AUTOSAR XML (schema 4-0-3)
standard types defined: Boolean, UInt16, UInt32, UInt8
package /AUTOSAR_Platform/DataConstrs
  range DC_Boolean: raw 0..1
  range DC_UInt16: raw 0..65535
  range DC_UInt8: raw 0..255
package /PATAC/MSM/ComponentTypes
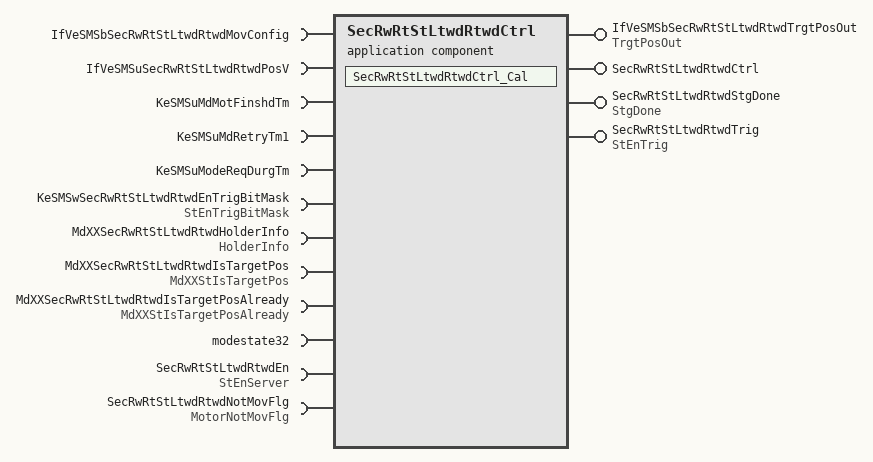
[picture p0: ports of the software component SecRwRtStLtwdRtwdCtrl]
  application sw component type SecRwRtStLtwdRtwdCtrl
    4 x provide port:
      IfVeSMSbSecRwRtStLtwdRtwdTrgtPosOut: nonqueued-sender-com-spec=data-element=TrgtPosOut/Val, provided-interface=TrgtPosOut
      SecRwRtStLtwdRtwdCtrl: server-com-spec{operation=Cal, queue-length=1}, provided-interface=SecRwRtStLtwdRtwdCtrl
      SecRwRtStLtwdRtwdStgDone: nonqueued-sender-com-spec{data-element=StgDone/Val, init-value=0}, provided-interface=StgDone
      SecRwRtStLtwdRtwdTrig: nonqueued-sender-com-spec{data-element=StEnTrig/Val, init-value=0}, provided-interface=StEnTrig
    12 x require port:
      IfVeSMSbSecRwRtStLtwdRtwdMovConfig: nonqueued-receiver-com-spec{data-element=IfVeSMSbSecRwRtStLtwdRtwdMovConfig/Val, filter=data-filter-type=ALWAYS, init-value=0}, required-interface=IfVeSMSbSecRwRtStLtwdRtwdMovConfig
      IfVeSMSuSecRwRtStLtwdRtwdPosV: nonqueued-receiver-com-spec{data-element=IfVeSMSuSecRwRtStLtwdRtwdPosV/Val, filter=data-filter-type=ALWAYS, init-value=0}, required-interface=IfVeSMSuSecRwRtStLtwdRtwdPosV
      KeSMSuMdMotFinshdTm: parameter-require-com-spec{init-value=0, parameter=KeSMSuMdMotFinshdTm/Val}, required-interface=KeSMSuMdMotFinshdTm
      KeSMSuMdRetryTm1: parameter-require-com-spec{init-value=0, parameter=KeSMSuMdRetryTm1/Val}, required-interface=KeSMSuMdRetryTm1
      KeSMSuModeReqDurgTm: parameter-require-com-spec{init-value=0, parameter=KeSMSuModeReqDurgTm/Val}, required-interface=KeSMSuModeReqDurgTm
      KeSMSwSecRwRtStLtwdRtwdEnTrigBitMask: parameter-require-com-spec{init-value=6153, parameter=StEnTrigBitMask/Val}, required-interface=StEnTrigBitMask
      MdXXSecRwRtStLtwdRtwdHolderInfo: nonqueued-receiver-com-spec{data-element=HolderInfo/Val, filter=data-filter-type=ALWAYS, init-value=0}, required-interface=HolderInfo
      MdXXSecRwRtStLtwdRtwdIsTargetPos: nonqueued-receiver-com-spec{data-element=MdXXStIsTargetPos/Val, filter=data-filter-type=ALWAYS, init-value=0}, required-interface=MdXXStIsTargetPos
      MdXXSecRwRtStLtwdRtwdIsTargetPosAlready: nonqueued-receiver-com-spec{data-element=MdXXStIsTargetPosAlready/Val, filter=data-filter-type=ALWAYS, init-value=0}, required-interface=MdXXStIsTargetPosAlready
      modestate32: nonqueued-receiver-com-spec{data-element=modestate32/Val, filter=data-filter-type=ALWAYS, init-value=0}, required-interface=modestate32
      SecRwRtStLtwdRtwdEn: required-com-specs=[Clear, Get, Set], required-interface=StEnServer
      SecRwRtStLtwdRtwdNotMovFlg: nonqueued-receiver-com-spec{data-element=MotorNotMovFlg/Val, filter=data-filter-type=ALWAYS, init-value=0}, required-interface=MotorNotMovFlg
    behavior SecRwRtStLtwdRtwdCtrl_InternalBehavior
      operation invoked event OIT_SecRwRtStLtwdRtwdCtrl_Cal_SecRwRtStLtwdRtwdCtrl_Cal: start-on-event=SecRwRtStLtwdRtwdCtrl_Cal, operation=SecRwRtStLtwdRtwdCtrl.Cal
      runnable SecRwRtStLtwdRtwdCtrl_Cal
        data-receive-point-by-arguments:
          7 x access:
            REC_IfVeSMSbSecRwRtStLtwdRtwdMovConfig_Val: accessed-variable=IfVeSMSbSecRwRtStLtwdRtwdMovConfig.Val
            REC_IfVeSMSuSecRwRtStLtwdRtwdPosV_Val: accessed-variable=IfVeSMSuSecRwRtStLtwdRtwdPosV.Val
            REC_MdXXSecRwRtStLtwdRtwdHolderInfo_Val: accessed-variable=MdXXSecRwRtStLtwdRtwdHolderInfo.Val
            REC_MdXXSecRwRtStLtwdRtwdIsTargetPos_Val: accessed-variable=MdXXSecRwRtStLtwdRtwdIsTargetPos.Val
            REC_MdXXSecRwRtStLtwdRtwdIsTargetPosAlready_Val: accessed-variable=MdXXSecRwRtStLtwdRtwdIsTargetPosAlready.Val
            REC_modestate32_Val: accessed-variable=modestate32.Val
            REC_SecRwRtStLtwdRtwdNotMovFlg_Val: accessed-variable=SecRwRtStLtwdRtwdNotMovFlg.Val
        data-send-points:
          access SEND_IfVeSMSbSecRwRtStLtwdRtwdTrgtPosOut_Val: accessed-variable=IfVeSMSbSecRwRtStLtwdRtwdTrgtPosOut.Val
          access SEND_SecRwRtStLtwdRtwdStgDone_Val: accessed-variable=SecRwRtStLtwdRtwdStgDone.Val
          access SEND_SecRwRtStLtwdRtwdTrig_Val: accessed-variable=SecRwRtStLtwdRtwdTrig.Val
        4 x parameter access:
          PA_KeSMSuMdMotFinshdTm_Val: accessed-parameter=KeSMSuMdMotFinshdTm.Val
          PA_KeSMSuMdRetryTm1_Val: accessed-parameter=KeSMSuMdRetryTm1.Val
          PA_KeSMSuModeReqDurgTm_Val: accessed-parameter=KeSMSuModeReqDurgTm.Val
          PA_KeSMSwSecRwRtStLtwdRtwdEnTrigBitMask_Val: accessed-parameter=KeSMSwSecRwRtStLtwdRtwdEnTrigBitMask.Val
        sync call SC_SecRwRtStLtwdRtwdEn_Get: operation=SecRwRtStLtwdRtwdEn.Get, timeout=0
  swc implementation SecRwRtStLtwdRtwdCtrl_Implementation: behavior=SecRwRtStLtwdRtwdCtrl_InternalBehavior
    code-descriptors:
      code Default: artifact-descriptors=autosar-engineering-object={short-label=Default, category=SWSRC}
package /PATAC/MSM/ModeAdjust/CalPortInterface
  parameter interface KeSMSuMdMotFinshdTm
    parameter data prototype Val: sw-calibration-access=READ-WRITE, type=UInt16
  parameter interface KeSMSuModeReqDurgTm
    parameter data prototype Val: sw-calibration-access=READ-WRITE, type=UInt16
  parameter interface StEnTrigBitMask
    parameter data prototype Val: sw-calibration-access=READ-WRITE, type=UInt32
package /PATAC/MSM/ModeAdjust/Interfaces
  sender receiver interface IfVeSMSuSecRwRtStLtwdRtwdPosV: invalidation-policy{data-element=IfVeSMSuSecRwRtStLtwdRtwdPosV/Val, handle-invalid=DONT-INVALIDATE}
    data Val: type=Boolean
package /PATAC/MSM/ModeAdjust/PortInterface
  client server interface SecRwRtStLtwdRtwdCtrl
    operation Cal
  client server interface StEnServer
    operation Clear
      arg data: type=UInt8, direction=IN, server-argument-impl-policy=USE-ARGUMENT-TYPE
    operation Get
      arg data: type=UInt32, direction=OUT, server-argument-impl-policy=USE-ARGUMENT-TYPE
    operation Set
      arg data: type=UInt8, direction=IN, server-argument-impl-policy=USE-ARGUMENT-TYPE
  8 x sender receiver interface:
    HolderInfo: invalidation-policy{data-element=HolderInfo/Val, handle-invalid=DONT-INVALIDATE}
      data Val: type=UInt32
    MdXXStIsTargetPos: invalidation-policy{data-element=MdXXStIsTargetPos/Val, handle-invalid=DONT-INVALIDATE}
      data Val: type=UInt32
    MdXXStIsTargetPosAlready: invalidation-policy{data-element=MdXXStIsTargetPosAlready/Val, handle-invalid=DONT-INVALIDATE}
      data Val: type=UInt32
    modestate32: invalidation-policy{data-element=modestate32/Val, handle-invalid=DONT-INVALIDATE}
      data Val: type=UInt32
    MotorNotMovFlg: invalidation-policy{data-element=MotorNotMovFlg/Val, handle-invalid=DONT-INVALIDATE}
      data Val: type=Boolean
    StEnTrig: invalidation-policy{data-element=StEnTrig/Val, handle-invalid=DONT-INVALIDATE}
      data Val: type=Boolean
    StgDone: invalidation-policy{data-element=StgDone/Val, handle-invalid=DONT-INVALIDATE}
      data Val: type=Boolean
    TrgtPosOut: invalidation-policy{data-element=TrgtPosOut/Val, handle-invalid=DONT-INVALIDATE}
      data Val: type=Boolean
package /PATAC/MSM/PortInterfaces
  parameter interface KeSMSuMdRetryTm1
    parameter data prototype Val: sw-calibration-access=READ-WRITE, type=UInt8
  sender receiver interface IfVeSMSbSecRwRtStLtwdRtwdMovConfig: invalidation-policy{data-element=IfVeSMSbSecRwRtStLtwdRtwdMovConfig/Val, handle-invalid=DONT-INVALIDATE}
    data Val: type=Boolean
